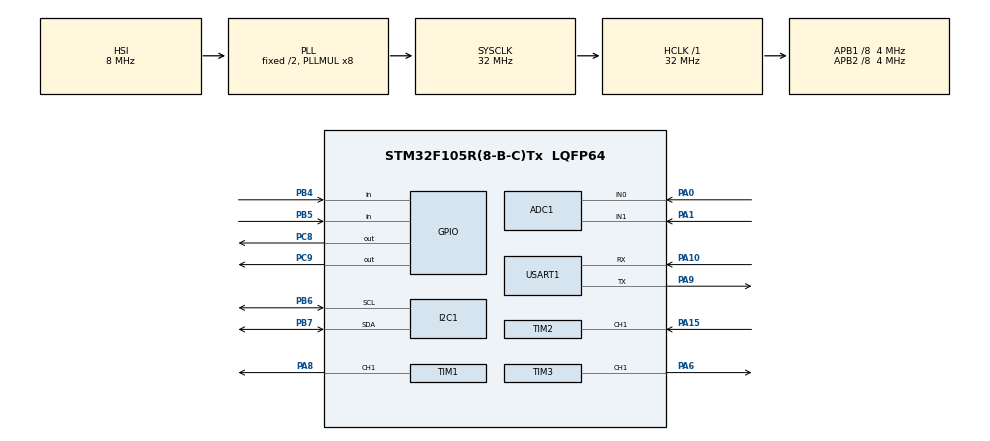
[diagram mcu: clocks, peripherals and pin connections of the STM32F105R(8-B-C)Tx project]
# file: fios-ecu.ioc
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ADC1.Channel-0\#ChannelRegularConversion=ADC_CHANNEL_0
ADC1.NbrOfConversionFlag=1
ADC1.Rank-0\#ChannelRegularConversion=1
ADC1.SamplingTime-0\#ChannelRegularConversion=ADC_SAMPLETIME_1CYCLE_5
ADC1.master=1
Mcu.Family=STM32F1
Mcu.Name=STM32F105R(8-B-C)Tx
Mcu.Package=LQFP64
NVIC.PriorityGroup=NVIC_PRIORITYGROUP_4
NVIC.TIM2_IRQn=true\:0\:0\:false\:false\:true
NVIC.TIM3_IRQn=true\:0\:0\:false\:false\:true
NVIC.TIM7_IRQn=true\:0\:0\:false\:false\:true
NVIC.USART1_IRQn=true\:0\:0\:false\:false\:true
PA0-WKUP.Signal=ADCx_IN0
PA1.Signal=ADCx_IN1
PA10.Mode=Asynchronous
PA10.Signal=USART1_RX
PA15.Signal=S_TIM2_CH1_ETR
PA6.GPIO_ModeDefaultPP=GPIO_MODE_AF_PP
PA6.GPIO_Speed=GPIO_SPEED_FREQ_HIGH
PA6.Signal=S_TIM3_CH1
PA8.Signal=S_TIM1_CH1
PA9.Mode=Asynchronous
PA9.Signal=USART1_TX
PB4.Signal=GPIO_Input
PB5.Signal=GPIO_Input
PB6.Mode=I2C
PB6.Signal=I2C1_SCL
PB7.Mode=I2C
PB7.Signal=I2C1_SDA
PC8.Signal=GPIO_Output
PC9.Signal=GPIO_Output
ProjectManager.HeapSize=0x200
ProjectManager.StackSize=0x400
ProjectManager.TargetToolchain=SW4STM32
RCC.AHBFreq_Value=32000000
RCC.APB1CLKDivider=RCC_HCLK_DIV8
RCC.APB1Freq_Value=4000000
RCC.APB1TimFreq_Value=8000000
RCC.APB2CLKDivider=RCC_HCLK_DIV8
RCC.APB2Freq_Value=4000000
RCC.APB2TimFreq_Value=8000000
RCC.HCLKFreq_Value=32000000
RCC.PLLMUL=RCC_PLL_MUL8
RCC.SYSCLKFreq_VALUE=32000000
RCC.SYSCLKSource=RCC_SYSCLKSOURCE_PLLCLK
RCC.USBFreq_Value=21333333.333333332
SH.ADCx_IN0.0=ADC1_IN0,IN0
SH.ADCx_IN1.0=ADC1_IN1,IN1
SH.S_TIM1_CH1.0=TIM1_CH1,PWM Generation1 CH1
SH.S_TIM2_CH1_ETR.0=TIM2_CH1,Input_Capture1_from_TI1
SH.S_TIM2_CH1_ETR.1=TIM2_CH1,Input_Capture2_from_TI1
SH.S_TIM3_CH1.0=TIM3_CH1,PWM Generation1 CH1
TIM1.ClockDivision=TIM_CLOCKDIVISION_DIV2
TIM1.Period=65523
TIM1.Prescaler=1
TIM1.Pulse-PWM\ Generation1\ CH1=0x7FFF
TIM1.TIM_MasterOutputTrigger=TIM_TRGO_ENABLE
TIM2.Channel-Input_Capture2_from_TI1=TIM_CHANNEL_2
TIM2.ICPolarity_CH2=TIM_INPUTCHANNELPOLARITY_FALLING
TIM2.Period=65535
TIM2.Prescaler=1
TIM2.TIM_MasterOutputTrigger=TIM_TRGO_UPDATE
TIM2.TIM_MasterSlaveMode=TIM_MASTERSLAVEMODE_DISABLE
TIM3.Period=65535
TIM3.Prescaler=1
TIM3.Pulse-PWM\ Generation1\ CH1=32767
TIM3.TIM_MasterOutputTrigger=TIM_TRGO_RESET
TIM3.TIM_MasterSlaveMode=TIM_MASTERSLAVEMODE_DISABLE
TIM7.Period=31
TIM7.Prescaler=64000
VP_TIM1_VS_ClockSourceINT.Mode=Internal
VP_TIM1_VS_OPM.Mode=OPM_bit
VP_TIM2_VS_ClockSourceINT.Mode=Internal
VP_TIM2_VS_ClockSourceITR.Mode=TriggerSource_ITR0
VP_TIM3_VS_ClockSourceINT.Mode=Internal
VP_TIM3_VS_ClockSourceITR.Mode=TriggerSource_ITR0
VP_TIM7_VS_ClockSourceINT.Mode=Enable_Timer
board=fios-ecu

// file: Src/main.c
/**
  ******************************************************************************
  * File Name          : main.c
  * Description        : Main program body
  ******************************************************************************
  *
  * COPYRIGHT(c) 2019 STMicroelectronics
  *
  * Redistribution and use in source and binary forms, with or without modification,
  * are permitted provided that the following conditions are met:
  *   1. Redistributions of source code must retain the above copyright notice,
  *      this list of conditions and the following disclaimer.
  *   2. Redistributions in binary form must reproduce the above copyright notice,
  *      this list of conditions and the following disclaimer in the documentation
  *      and/or other materials provided with the distribution.
  *   3. Neither the name of STMicroelectronics nor the names of its contributors
  *      may be used to endorse or promote products derived from this software
  *      without specific prior written permission.
  *
  * THIS SOFTWARE IS PROVIDED BY THE COPYRIGHT HOLDERS AND CONTRIBUTORS "AS IS"
  * AND ANY EXPRESS OR IMPLIED WARRANTIES, INCLUDING, BUT NOT LIMITED TO, THE
  * IMPLIED WARRANTIES OF MERCHANTABILITY AND FITNESS FOR A PARTICULAR PURPOSE ARE
  * DISCLAIMED. IN NO EVENT SHALL THE COPYRIGHT HOLDER OR CONTRIBUTORS BE LIABLE
  * FOR ANY DIRECT, INDIRECT, INCIDENTAL, SPECIAL, EXEMPLARY, OR CONSEQUENTIAL
  * DAMAGES (INCLUDING, BUT NOT LIMITED TO, PROCUREMENT OF SUBSTITUTE GOODS OR
  * SERVICES; LOSS OF USE, DATA, OR PROFITS; OR BUSINESS INTERRUPTION) HOWEVER
  * CAUSED AND ON ANY THEORY OF LIABILITY, WHETHER IN CONTRACT, STRICT LIABILITY,
  * OR TORT (INCLUDING NEGLIGENCE OR OTHERWISE) ARISING IN ANY WAY OUT OF THE USE
  * OF THIS SOFTWARE, EVEN IF ADVISED OF THE POSSIBILITY OF SUCH DAMAGE.
  *
  ******************************************************************************
  */
#include "stm32f1xx_hal.h"
#include "adc.h"
#include "i2c.h"
#include "tim.h"
#include "usart.h"
#include "gpio.h"

/* USER CODE BEGIN PV */
/* Private variables ---------------------------------------------------------*/

/* USER CODE END PV */

void SystemClock_Config(void);

/* USER CODE BEGIN PFP */
/* Private function prototypes -----------------------------------------------*/

/* USER CODE END PFP */

int main(void)
{

  /* MCU Configuration----------------------------------------------------------*/

  /* Reset of all peripherals, Initializes the Flash interface and the Systick. */
  HAL_Init();

  /* Configure the system clock */
  SystemClock_Config();

  /* Initialize all configured peripherals */
  MX_GPIO_Init();
  MX_ADC1_Init();
  MX_I2C1_Init();
  MX_TIM1_Init();
  MX_TIM2_Init();
  MX_TIM3_Init();
  MX_TIM7_Init();
  MX_USART1_UART_Init();

  /* Infinite loop */
  while (1)
  {

  /* USER CODE BEGIN 3 */
      ecu_start_main_loop();
  }
  /* USER CODE END 3 */

}

/** System Clock Configuration
*/
void SystemClock_Config(void)
{

  RCC_OscInitTypeDef RCC_OscInitStruct;
  RCC_ClkInitTypeDef RCC_ClkInitStruct;
  RCC_PeriphCLKInitTypeDef PeriphClkInit;

  RCC_OscInitStruct.OscillatorType = RCC_OSCILLATORTYPE_HSI;
  RCC_OscInitStruct.HSIState = RCC_HSI_ON;
  RCC_OscInitStruct.HSICalibrationValue = 16;
  RCC_OscInitStruct.Prediv1Source = RCC_PREDIV1_SOURCE_HSE;
  RCC_OscInitStruct.PLL.PLLState = RCC_PLL_ON;
  RCC_OscInitStruct.PLL.PLLSource = RCC_PLLSOURCE_HSI_DIV2;
  RCC_OscInitStruct.PLL.PLLMUL = RCC_PLL_MUL8;
  RCC_OscInitStruct.PLL2.PLL2State = RCC_PLL_NONE;
  HAL_RCC_OscConfig(&RCC_OscInitStruct);

  RCC_ClkInitStruct.ClockType = RCC_CLOCKTYPE_HCLK|RCC_CLOCKTYPE_SYSCLK
                              |RCC_CLOCKTYPE_PCLK1|RCC_CLOCKTYPE_PCLK2;
  RCC_ClkInitStruct.SYSCLKSource = RCC_SYSCLKSOURCE_PLLCLK;
  RCC_ClkInitStruct.AHBCLKDivider = RCC_SYSCLK_DIV1;
  RCC_ClkInitStruct.APB1CLKDivider = RCC_HCLK_DIV8;
  RCC_ClkInitStruct.APB2CLKDivider = RCC_HCLK_DIV8;
  HAL_RCC_ClockConfig(&RCC_ClkInitStruct, FLASH_LATENCY_1);

  PeriphClkInit.PeriphClockSelection = RCC_PERIPHCLK_ADC;
  PeriphClkInit.AdcClockSelection = RCC_ADCPCLK2_DIV2;
  HAL_RCCEx_PeriphCLKConfig(&PeriphClkInit);

  HAL_SYSTICK_Config(HAL_RCC_GetHCLKFreq()/1000);

  HAL_SYSTICK_CLKSourceConfig(SYSTICK_CLKSOURCE_HCLK);

  __HAL_RCC_PLLI2S_ENABLE();

  /* SysTick_IRQn interrupt configuration */
  HAL_NVIC_SetPriority(SysTick_IRQn, 0, 0);
}

/************************ (C) COPYRIGHT STMicroelectronics *****END OF FILE****/
